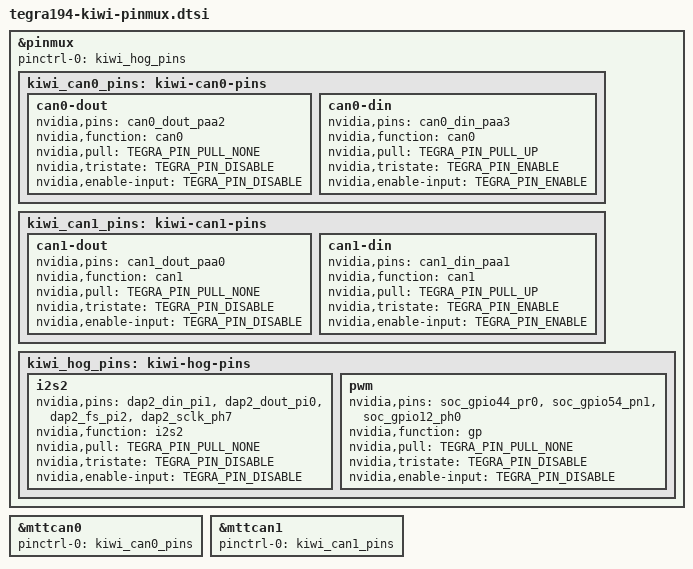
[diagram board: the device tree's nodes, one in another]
/*
 * Kiwi pad config (CAN, I2S2, PWM), shared by kiwi-xavier (included from
 * tegra194-agx-kiwi-AGX.dts) and the jetson-xavier devkit (appended to the stock
 * tegra194-p2888-0001-p2822-0000.dts by linux-tegra_%.bbappend). Same SoC pads
 * on both boards; rover configuration.sh used to set them with devmem on both.
 */
#include <dt-bindings/pinctrl/pinctrl-tegra.h>

/*
 * CAN pads: MB1 BCT (tegra19x-mb1-pinmux-p2888-0000-a04-p2822-0000-b01.cfg)
 * leaves PAA0..PAA3 as GPIO (0xc055/0xc059). rover configuration.sh used to
 * flip them to the CAN SFIO with `busybox devmem 0x0c3030{00,08,10,18}`
 * (0xc400 dout / 0xc458 din), which kernel lockdown (secure boot) blocks.
 * Same config here, applied by pinctrl when mttcan probes; pinctrl does a
 * read-modify-write, so MB1's drive-type bits 14/15 are kept as devmem had them.
 */
&pinmux {
	kiwi_can0_pins: kiwi-can0-pins {
		can0-dout {
			nvidia,pins = "can0_dout_paa2";
			nvidia,function = "can0";
			nvidia,pull = <TEGRA_PIN_PULL_NONE>;
			nvidia,tristate = <TEGRA_PIN_DISABLE>;
			nvidia,enable-input = <TEGRA_PIN_DISABLE>;
		};
		can0-din {
			nvidia,pins = "can0_din_paa3";
			nvidia,function = "can0";
			nvidia,pull = <TEGRA_PIN_PULL_UP>;
			nvidia,tristate = <TEGRA_PIN_ENABLE>;
			nvidia,enable-input = <TEGRA_PIN_ENABLE>;
		};
	};

	kiwi_can1_pins: kiwi-can1-pins {
		can1-dout {
			nvidia,pins = "can1_dout_paa0";
			nvidia,function = "can1";
			nvidia,pull = <TEGRA_PIN_PULL_NONE>;
			nvidia,tristate = <TEGRA_PIN_DISABLE>;
			nvidia,enable-input = <TEGRA_PIN_DISABLE>;
		};
		can1-din {
			nvidia,pins = "can1_din_paa1";
			nvidia,function = "can1";
			nvidia,pull = <TEGRA_PIN_PULL_UP>;
			nvidia,tristate = <TEGRA_PIN_ENABLE>;
			nvidia,enable-input = <TEGRA_PIN_ENABLE>;
		};
	};
};

&mttcan0 {
	pinctrl-names = "default";
	pinctrl-0 = <&kiwi_can0_pins>;
};

&mttcan1 {
	pinctrl-names = "default";
	pinctrl-0 = <&kiwi_can1_pins>;
};

/*
 * I2S2 speaker pads + PWM pads: rover configuration.sh interfacesConfiguration()
 * used to set these with busybox devmem (blocked under kernel lockdown). MB1 BCT
 * leaves them GPIO, pull-down, tristated, input-enabled; devmem wrote:
 *   0x02434000/08/10/18 = 0x400 -> dap2_{din,dout,fs,sclk}: i2s2, no pull, driven, input off
 *   0x02430040 = 0x401 (pin13 pwm8), 0x02434090 = 0x401 (pin18 pwm5),
 *   0x02440020 = 0x402 (pin15 pwm1) -> "gp" function, no pull, driven, input off
 * No driver here owns these pads, so apply them as pinmux hogs at pinctrl probe.
 */
&pinmux {
	pinctrl-names = "default";
	pinctrl-0 = <&kiwi_hog_pins>;

	kiwi_hog_pins: kiwi-hog-pins {
		i2s2 {
			nvidia,pins = "dap2_din_pi1", "dap2_dout_pi0",
				      "dap2_fs_pi2", "dap2_sclk_ph7";
			nvidia,function = "i2s2";
			nvidia,pull = <TEGRA_PIN_PULL_NONE>;
			nvidia,tristate = <TEGRA_PIN_DISABLE>;
			nvidia,enable-input = <TEGRA_PIN_DISABLE>;
		};
		pwm {
			nvidia,pins = "soc_gpio44_pr0",	/* pin13 pwm8 */
				      "soc_gpio54_pn1",	/* pin15 pwm1 */
				      "soc_gpio12_ph0";	/* pin18 pwm5 */
			nvidia,function = "gp";
			nvidia,pull = <TEGRA_PIN_PULL_NONE>;
			nvidia,tristate = <TEGRA_PIN_DISABLE>;
			nvidia,enable-input = <TEGRA_PIN_DISABLE>;
		};
	};
};
